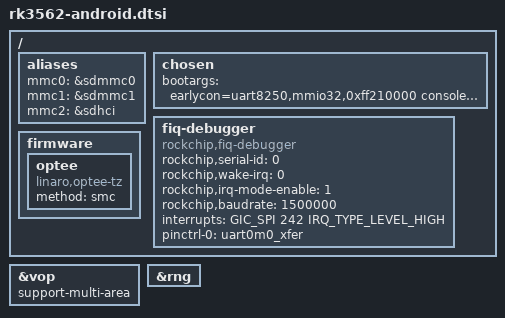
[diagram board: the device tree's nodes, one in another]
// SPDX-License-Identifier: (GPL-2.0+ OR MIT)
/*
 * Copyright (c) 2022 Rockchip Electronics Co., Ltd.
 *
 */

/ {
	aliases {
		mmc0 = &sdmmc0;
		mmc1 = &sdmmc1;
		mmc2 = &sdhci;
	};

	chosen: chosen {
		bootargs = "earlycon=uart8250,mmio32,0xff210000 console=ttyFIQ0";
	};

	fiq-debugger {
		compatible = "rockchip,fiq-debugger";
		rockchip,serial-id = <0>;
		rockchip,wake-irq = <0>;
		/* If enable uart uses irq instead of fiq */
		rockchip,irq-mode-enable = <1>;
		rockchip,baudrate = <1500000>;  /* Only 115200 and 1500000 */
		interrupts = <GIC_SPI 242 IRQ_TYPE_LEVEL_HIGH>;
		pinctrl-names = "default";
		pinctrl-0 = <&uart0m0_xfer>;
		status = "okay";
	};

	firmware {
		optee: optee {
			compatible = "linaro,optee-tz";
			method = "smc";
		};
	};
};

&vop {
	support-multi-area;
};

&rng {
	status = "okay";
};
